# ESP32-C61 register map
Vendor: ESPRESSIF SYSTEMS (SHANGHAI) CO., LTD.; Series: ESP32 C-Series; File version: 1
CPU: RV32IMAC r0p0, little endian, no MPU, no FPU, 0 interrupt priority bits
Address unit: 32 bits
Registers are 32-bit, read-write, reset 0x0 unless marked. A register's access mark holds for its fields unless they carry their own. Offsets are from the block's base; [hi:lo] are bit positions.

## LP_TIMER — Low-power Timer
Base 0x600B0C00
0x00 TAR0_LOW — RTC timer threshold low bits register0
  [31:0] MAIN_TIMER_TAR_LOW0 — Configures the lower 32 bits of the trigger threshold for the RTC timer compare0.
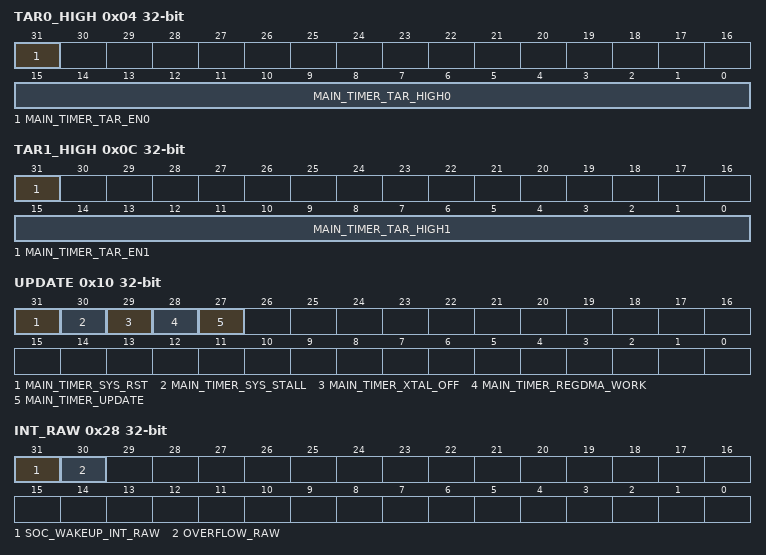
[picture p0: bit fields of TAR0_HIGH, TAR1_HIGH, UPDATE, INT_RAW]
0x04 TAR0_HIGH access per field — RTC timer enable register0
  [31] MAIN_TIMER_TAR_EN0 wo — Configure this bit to enable the timer compare0 alarm.\\0: Disable \\1: Enable
  [15:0] MAIN_TIMER_TAR_HIGH0 rw — Configures the higher 16 bits of the trigger threshold for the RTC timer compare0
0x08 TAR1_LOW — RTC timer threshold low bits register1
  [31:0] MAIN_TIMER_TAR_LOW1 — Configures the lower 32 bits of the trigger threshold for the RTC timer compare1.
0x0C TAR1_HIGH access per field — RTC timer threshold high bits register0
  [31] MAIN_TIMER_TAR_EN1 wo — Configure this bit to enable the timer compare1 alarm.\\0: Disable \\1: Enable
  [15:0] MAIN_TIMER_TAR_HIGH1 rw — Configures the higher 16 bits of the trigger threshold for the RTC timer compare1
0x10 UPDATE access per field — RTC timer update control register
  [31] MAIN_TIMER_SYS_RST rw — Selects the triggering condition for the RTC timer,triggered when resetting digital core completes
  [30] MAIN_TIMER_SYS_STALL rw — Selects the triggering condition for the RTC timer,triggered when CPU enters or exits the stall state.
  [29] MAIN_TIMER_XTAL_OFF rw — Selects the triggering condition for the RTC timer,triggered when XTAL\_CLK powers up
  [28] MAIN_TIMER_REGDMA_WORK rw — Selects the triggering condition for the RTC timer,triggered when regdma working
  [27] MAIN_TIMER_UPDATE wo — Triggers timer by software
0x14 MAIN_BUF0_LOW ro — RTC timer buffer0 low bits register
  [31:0] MAIN_TIMER_BUF0_LOW
0x18 MAIN_BUF0_HIGH ro — RTC timer buffer0 high bits register
  [15:0] MAIN_TIMER_BUF0_HIGH
0x1C MAIN_BUF1_LOW ro — RTC timer buffer1 low bits register
  [31:0] MAIN_TIMER_BUF1_LOW
0x20 MAIN_BUF1_HIGH ro — RTC timer buffer1 high bits register
  [15:0] MAIN_TIMER_BUF1_HIGH
0x24 MAIN_OVERFLOW wo
  [31] MAIN_TIMER_ALARM_LOAD
0x28 INT_RAW — RTC timer interrupt raw register
  [31] SOC_WAKEUP_INT_RAW — Triggered when RTC main timer reach the target value.
  [30] OVERFLOW_RAW — Triggered when counter register of RTC main timer overflow.
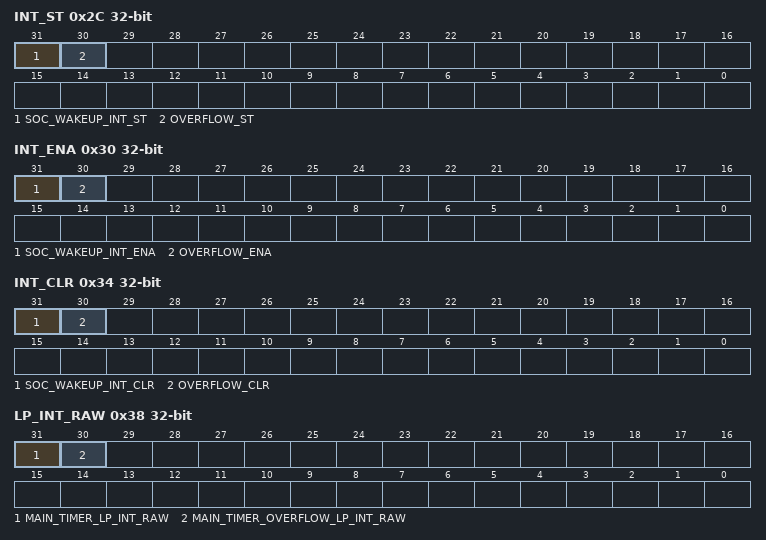
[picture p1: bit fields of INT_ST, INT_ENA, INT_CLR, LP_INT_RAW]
0x2C INT_ST ro — RTC timer interrupt status register
  [31] SOC_WAKEUP_INT_ST — Status of RTC main timer interrupt .
  [30] OVERFLOW_ST — Status of RTC main timer overflow interrupt .
0x30 INT_ENA — RTC timer interrupt enable register
  [31] SOC_WAKEUP_INT_ENA — Enable the RTC main timer interrupt..\\0 : Disable \\1: Enable
  [30] OVERFLOW_ENA — Enable the RTC main timer overflow interrupt..\\0 : Disable \\1: Enable
0x34 INT_CLR wo — RTC timer interrupt clear register
  [31] SOC_WAKEUP_INT_CLR — Clear the RTC main timer raw interrupt..
  [30] OVERFLOW_CLR — Clear the RTC main timer overflow raw interrupt..
0x38 LP_INT_RAW — RTC timer interrupt raw register(For ULP)
  [31] MAIN_TIMER_LP_INT_RAW — Triggered when RTC main timer reach the target value
  [30] MAIN_TIMER_OVERFLOW_LP_INT_RAW — Triggered when counter register of RTC main timer overflow
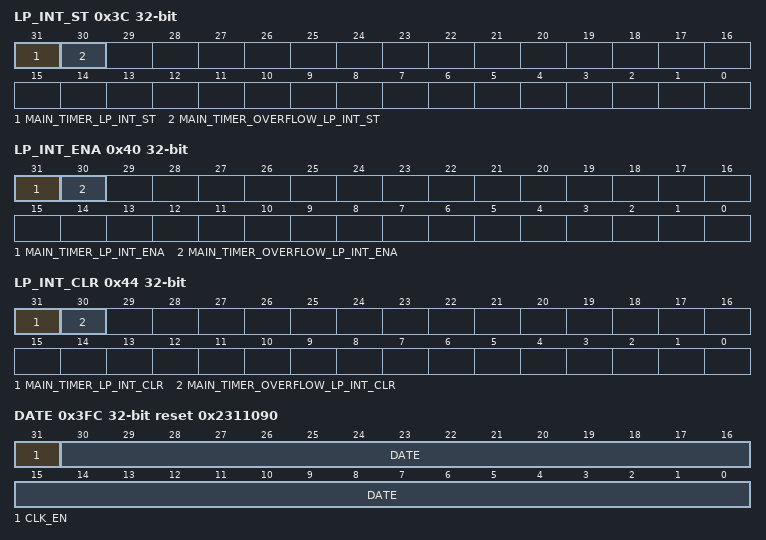
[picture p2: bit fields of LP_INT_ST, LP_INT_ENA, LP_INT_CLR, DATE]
0x3C LP_INT_ST ro — RTC timer interrupt status register(For ULP)
  [31] MAIN_TIMER_LP_INT_ST — Status of RTC main timer interrupt .
  [30] MAIN_TIMER_OVERFLOW_LP_INT_ST — Status of RTC main timer overflow interrupt .
0x40 LP_INT_ENA — RTC timer interrupt enable register(For ULP)
  [31] MAIN_TIMER_LP_INT_ENA — Enable the RTC main timer interrupt..\\0 : Disable \\1: Enable
  [30] MAIN_TIMER_OVERFLOW_LP_INT_ENA — Enable the RTC main timer overflow interrupt..\\0 : Disable \\1: Enable
0x44 LP_INT_CLR wo — RTC timer interrupt clear register(For ULP)
  [31] MAIN_TIMER_LP_INT_CLR — Clear the RTC main timer clear interrupt..
  [30] MAIN_TIMER_OVERFLOW_LP_INT_CLR — Clear the RTC main timer overflow clear interrupt..
0x3FC DATE reset 0x2311090 — need_des
  [31] CLK_EN — need_des
  [30:0] DATE — Version data
